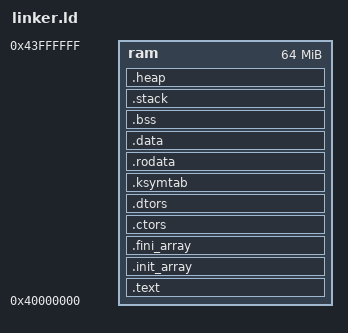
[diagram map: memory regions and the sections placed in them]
/*
 * linker.ld
 *
 * Copyright(c) 2007-2022 Jianjun Jiang <8192542@qq.com>
 * Copyright(c) 2024 Victor Suarez Rovere <suarezvictor@gmail.com>
 * Official site: http://xboot.org
 * Mobile phone: +86-18665388956
 * QQ: 8192542
 *
 * Permission is hereby granted, free of charge, to any person obtaining a copy
 * of this software and associated documentation files (the "Software"), to deal
 * in the Software without restriction, including without limitation the rights
 * to use, copy, modify, merge, publish, distribute, sublicense, and/or sell
 * copies of the Software, and to permit persons to whom the Software is
 * furnished to do so, subject to the following conditions:
 *
 * The above copyright notice and this permission notice shall be included in all
 * copies or substantial portions of the Software.
 *
 * THE SOFTWARE IS PROVIDED "AS IS", WITHOUT WARRANTY OF ANY KIND, EXPRESS OR
 * IMPLIED, INCLUDING BUT NOT LIMITED TO THE WARRANTIES OF MERCHANTABILITY,
 * FITNESS FOR A PARTICULAR PURPOSE AND NONINFRINGEMENT. IN NO EVENT SHALL THE
 * AUTHORS OR COPYRIGHT HOLDERS BE LIABLE FOR ANY CLAIM, DAMAGES OR OTHER
 * LIABILITY, WHETHER IN AN ACTION OF CONTRACT, TORT OR OTHERWISE, ARISING FROM,
 * OUT OF OR IN CONNECTION WITH THE SOFTWARE OR THE USE OR OTHER DEALINGS IN THE
 * SOFTWARE.
 *
 */

/* Copyright (c) 2020 SiFive Inc. */
/* SPDX-License-Identifier: Apache-2.0 */

OUTPUT_FORMAT("elf64-littleriscv", "elf64-littleriscv", "elf64-littleriscv")
OUTPUT_ARCH(riscv)
ENTRY(_start)

STACK_SIZE = 0x100000;

MEMORY
{
	ram  : org = 0x40000000, len = 64M
}

SECTIONS
{
	.text :
	{
		PROVIDE(__image_start = .);
		PROVIDE(__text_start = .);
		PROVIDE(__spl_start = .);
		build/crt0.o (.text*)
		. = ALIGN(8);
		PROVIDE(__spl_end = .);
		*(.text*)
		*(.init.text)
		*(.exit.text)
		PROVIDE(__text_end = .);
	} > ram
	PROVIDE(__spl_size = __spl_end - __spl_start);

    /* Include the list of initialization functions sorted. */
    .init_array ALIGN(8) :
    {
        PROVIDE_HIDDEN (_init_array_start = .);
        KEEP (*(SORT_BY_INIT_PRIORITY(.init_array.*) SORT_BY_INIT_PRIORITY(.ctors.*)))
        KEEP (*(.init_array EXCLUDE_FILE (*crtbegin.o *crtbegin?.o *crtend.o *crtend?.o ) .ctors))
        PROVIDE_HIDDEN (_init_array_end = .);        
    } > ram

    /* Include the list of termination functions sorted. */
    .fini_array ALIGN(8) :
    {
        PROVIDE_HIDDEN (_fini_array_start = .);
        KEEP (*(SORT_BY_INIT_PRIORITY(.fini_array.*) SORT_BY_INIT_PRIORITY(.dtors.*)))
        KEEP (*(.fini_array EXCLUDE_FILE (*crtbegin.o *crtbegin?.o *crtend.o *crtend?.o ) .dtors))
        PROVIDE_HIDDEN (_fini_array_end = .);
    } > ram

    .ctors : {
        KEEP (*crtbegin.o(.ctors))
        KEEP (*crtbegin?.o(.ctors))
        KEEP (*(EXCLUDE_FILE (*crtend.o *crtend?.o ) .ctors))
        KEEP (*(SORT(.ctors.*)))
        KEEP (*(.ctors))
    } >ram

    .dtors : {
        KEEP (*crtbegin.o(.dtors))
        KEEP (*crtbegin?.o(.dtors))
        KEEP (*(EXCLUDE_FILE (*crtend.o *crtend?.o ) .dtors))
        KEEP (*(SORT(.dtors.*)))
        KEEP (*(.dtors))
    } >ram
    
	.ksymtab ALIGN(16) :
	{
		PROVIDE(__ksymtab_start = .);
		KEEP(*(.ksymtab.text))
		PROVIDE(__ksymtab_end = .);
	} > ram

	.rodata ALIGN(8) :
	{
		PROVIDE(__rodata_start = .);
		*(.rodata*)
		*(.srodata*)
		PROVIDE(__rodata_end = .);
	} > ram

	.data ALIGN(8) :
	{
		PROVIDE(__data_start = .);
		PROVIDE(__global_pointer$ = . + 0x800);
		*(.sdata*)
		*(.data*)
		. = ALIGN(8);
  		PROVIDE(__data_end = .);
		PROVIDE(__image_end = .);
	} > ram

	.bss ALIGN(8) (NOLOAD) :
	{
		PROVIDE(__bss_start = .);
		*(.bss*)
		*(.sbss*)
		*(COMMON)
		. = ALIGN(8);
		PROVIDE(__bss_end = .);
	} > ram

	.stack ALIGN(16) (NOLOAD) :
	{
		PROVIDE(__stack_start = .);
		. += STACK_SIZE;
		. = ALIGN(16);
		PROVIDE(__stack_end = .);
	} > ram
	
	.heap ALIGN(16) (NOLOAD) :
	{
		PROVIDE(__heap_start = .);
		. = ORIGIN(ram) + LENGTH(ram);
		PROVIDE(__heap_end = .);
	} > ram

	/DISCARD/ : { *(.dynsym) }
	/DISCARD/ : { *(.dynstr*) }
	/DISCARD/ : { *(.dynamic*) }
	/DISCARD/ : { *(.interp*) }
}
